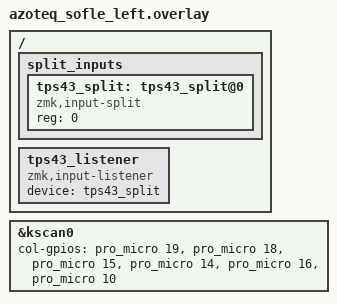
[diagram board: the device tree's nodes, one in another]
#include <dt-bindings/gpio/gpio.h>
#include "azoteq_sofle.dtsi"

&kscan0 {
    col-gpios
        = <&pro_micro 19 GPIO_ACTIVE_HIGH>
        , <&pro_micro 18 GPIO_ACTIVE_HIGH>
        , <&pro_micro 15 GPIO_ACTIVE_HIGH>
        , <&pro_micro 14 GPIO_ACTIVE_HIGH>
        , <&pro_micro 16 GPIO_ACTIVE_HIGH>
        , <&pro_micro 10 GPIO_ACTIVE_HIGH>
        ;
};

/ {
    split_inputs {
        #address-cells = <1>;
        #size-cells = <0>;

        tps43_split: tps43_split@0 {
            compatible = "zmk,input-split";
            reg = <0>;
            /* No device property here - this is a proxy on central side */
        };
    };

    tps43_listener: tps43_listener {
        compatible = "zmk,input-listener";
        device = <&tps43_split>;
        status = "okay";
    };
};
